VERSION ""

NS_ :

BS_:

BU_: ECU OBU

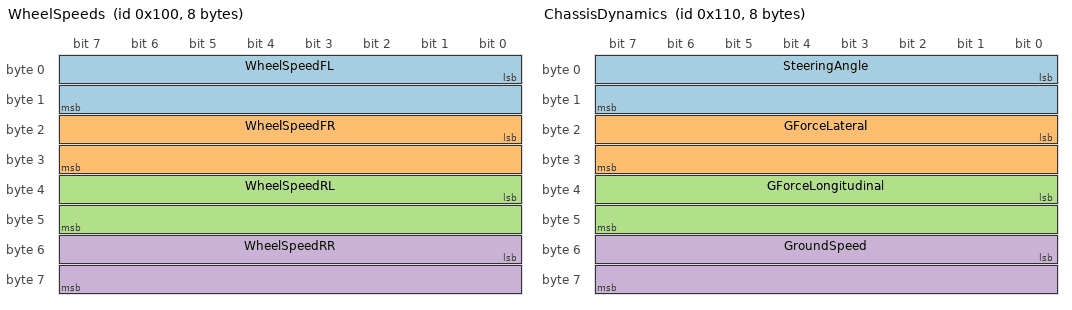
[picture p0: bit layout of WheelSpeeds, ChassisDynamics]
BO_ 256 WheelSpeeds: 8 ECU
 SG_ WheelSpeedFL : 0|16@1+ (0.1,0) [0|300] "km/h" OBU
 SG_ WheelSpeedFR : 16|16@1+ (0.1,0) [0|300] "km/h" OBU
 SG_ WheelSpeedRL : 32|16@1+ (0.1,0) [0|300] "km/h" OBU
 SG_ WheelSpeedRR : 48|16@1+ (0.1,0) [0|300] "km/h" OBU

BO_ 272 ChassisDynamics: 8 ECU
 SG_ SteeringAngle : 0|16@1- (0.1,0) [-720|720] "deg" OBU
 SG_ GForceLateral : 16|16@1- (0.001,0) [-5|5] "g" OBU
 SG_ GForceLongitudinal : 32|16@1- (0.001,0) [-5|5] "g" OBU
 SG_ GroundSpeed : 48|16@1+ (0.1,0) [0|300] "km/h" OBU

BO_ 288 Brakes: 4 ECU
 SG_ BrakePressureFront : 0|16@1+ (0.1,0) [0|200] "bar" OBU
 SG_ BrakePressureRear : 16|16@1+ (0.1,0) [0|200] "bar" OBU

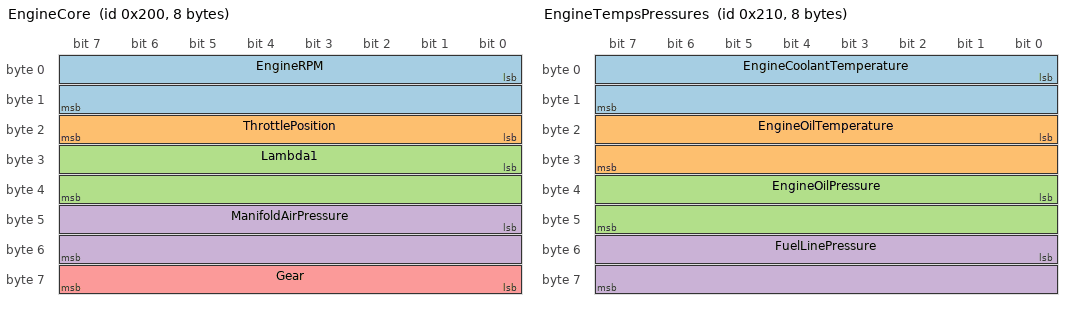
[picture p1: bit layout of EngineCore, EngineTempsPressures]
BO_ 512 EngineCore: 8 ECU
 SG_ EngineRPM : 0|16@1+ (1,0) [0|16000] "rpm" OBU
 SG_ ThrottlePosition : 16|8@1+ (1,0) [0|100] "%" OBU
 SG_ Lambda1 : 24|16@1+ (0.001,0) [0.5|1.5] "" OBU
 SG_ ManifoldAirPressure : 40|16@1+ (0.1,0) [0|300] "kPa" OBU
 SG_ Gear : 56|8@1+ (1,0) [0|255] "" OBU

BO_ 528 EngineTempsPressures: 8 ECU
 SG_ EngineCoolantTemperature : 0|16@1- (0.1,0) [-40|150] "degC" OBU
 SG_ EngineOilTemperature : 16|16@1- (0.1,0) [-40|170] "degC" OBU
 SG_ EngineOilPressure : 32|16@1+ (0.1,0) [0|10] "bar" OBU
 SG_ FuelLinePressure : 48|16@1+ (0.1,0) [0|10] "bar" OBU

BO_ 529 IntakeTempFuelUsed: 6 ECU
 SG_ ManifoldAirTemperature : 0|16@1- (0.1,0) [-40|120] "degC" OBU
 SG_ FuelUsedRaw : 16|32@1+ (1,0) [0|4294967295] "" OBU

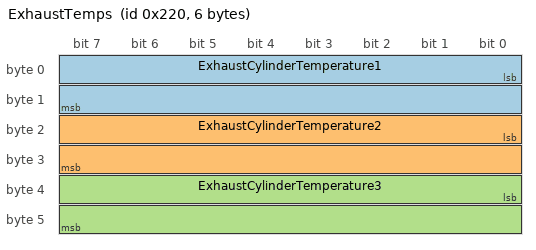
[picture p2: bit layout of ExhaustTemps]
BO_ 544 ExhaustTemps: 6 ECU
 SG_ ExhaustCylinderTemperature1 : 0|16@1- (1,0) [0|1200] "degC" OBU
 SG_ ExhaustCylinderTemperature2 : 16|16@1- (1,0) [0|1200] "degC" OBU
 SG_ ExhaustCylinderTemperature3 : 32|16@1- (1,0) [0|1200] "degC" OBU

CM_ BU_ ECU "Vehicle CAN2 transmitter: the ecu/ firmware simulator in dev/test, or a MoTeC M180 ECU/logger's User CAN output on CAN2 in production. See platform/esp-idf/firmware/ecu/main/main.c and docs/architecture/RFC-0001-UNIVERSAL-PACKET.md.";
CM_ BU_ OBU "ZC2X on-board unit; forwards every CAN ID unmodified over XBee/WiFi (see platform/esp-idf/firmware/obu/main/main.c can_init()).";
CM_ BO_ 256 "Wheel speed sensors. 100 Hz.";
CM_ BO_ 272 "Chassis dynamics: steering angle, lateral/longitudinal G, ground speed. 100 Hz.";
CM_ BO_ 288 "Brake line pressures, front/rear. 100 Hz.";
CM_ BO_ 512 "Core engine state: RPM, throttle, lambda, MAP, gear. 50 Hz.";
CM_ BO_ 528 "Engine temperatures and pressures. 10 Hz.";
CM_ BO_ 529 "Intake air temperature and cumulative fuel used. 10 Hz.";
CM_ BO_ 544 "Per-cylinder exhaust gas temperature (EGT). 5 Hz.";
CM_ SG_ 512 Gear "0=Neutral, 1-6=gear, 255=unknown. See VAL_ table below.";

BA_DEF_ BO_ "GenMsgCycleTime" INT 0 1000000;
BA_DEF_DEF_ "GenMsgCycleTime" 0;
BA_ "GenMsgCycleTime" BO_ 256 10;
BA_ "GenMsgCycleTime" BO_ 272 10;
BA_ "GenMsgCycleTime" BO_ 288 10;
BA_ "GenMsgCycleTime" BO_ 512 20;
BA_ "GenMsgCycleTime" BO_ 528 100;
BA_ "GenMsgCycleTime" BO_ 529 100;
BA_ "GenMsgCycleTime" BO_ 544 200;

VAL_ 512 Gear 0 "Neutral" 1 "1st" 2 "2nd" 3 "3rd" 4 "4th" 5 "5th" 6 "6th" 255 "Unknown" ;
